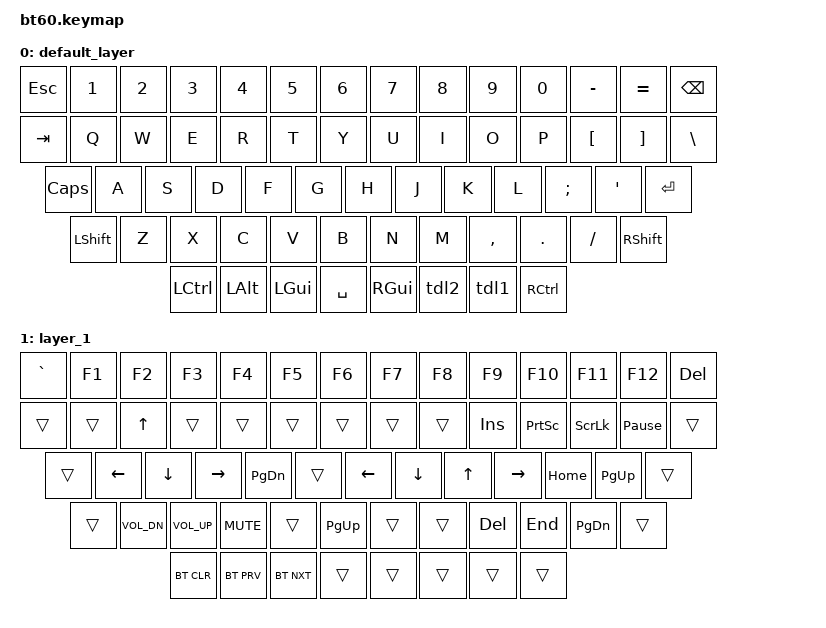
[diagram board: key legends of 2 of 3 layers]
#include <behaviors.dtsi>
#include <dt-bindings/zmk/keys.h>
#include <dt-bindings/zmk/bt.h>
#include <dt-bindings/zmk/rgb.h>
#include <dt-bindings/zmk/backlight.h>

/ {
  // Macros to combine layer tap dance with RGB underglow
  macros {
    m_togl1: macro_rgb_tog_layer_1 {
      compatible = "zmk,behavior-macro";
      #binding-cells = <0>;
      bindings = <&tog 1>,
        <&rgb_ug RGB_TOG>,
        <&rgb_ug RGB_COLOR_HSB(128,100,100)>  // Green
        ;
    };
    m_togl2: macro_rgb_tog_layer_2 {
      compatible = "zmk,behavior-macro";
      #binding-cells = <0>;
      bindings = <&tog 2>,
        <&rgb_ug RGB_TOG>,
        <&rgb_ug RGB_COLOR_HSB(0,100,100)>  // Red
        ;
    };
  };

  behaviors {
    // Tap Dance to change layer, tap once and hold for momentary layer, tap twice to toggle layer
    tdl1: tap_dance_layer_1 {
      compatible = "zmk,behavior-tap-dance";
      #binding-cells = <0>;
      tapping-term-ms = <200>;  // default: 200ms
      bindings = <&mo 1>, <&m_togl1>;
    };
    tdl2: tap_dance_layer_2 {
      compatible = "zmk,behavior-tap-dance";
      #binding-cells = <0>;
      tapping-term-ms = <200>;  // default: 200ms
      bindings = <&mo 2>, <&m_togl2>;
    };
  };


  keymap {
    compatible = "zmk,keymap";

    default_layer {
      // Qwerty
      bindings = <
      // ┏━━━━━━━━━┳━━━━━━━━┳━━━━━━━━┳━━━━━━━━┳━━━━━━━━┳━━━━━━━━┳━━━━━━━━┳━━━━━━━━┳━━━━━━━━┳━━━━━━━━┳━━━━━━━━┳━━━━━━━━━━━┳━━━━━━━━━━━┳━━━━━━━━━━━┓
      // ┃ Esc     ┃ 1      ┃ 2      ┃ 3      ┃ 4      ┃ 5      ┃   6    ┃ 7      ┃ 8      ┃ 9      ┃ 0      ┃ -         ┃ =         ┃ Backspace ┃
           &kp ESC   &kp N1   &kp N2   &kp N3   &kp N4   &kp N5   &kp N6   &kp N7   &kp N8   &kp N9   &kp N0   &kp MINUS   &kp EQUAL   &kp BSPC
      // ┣━━━━━━━━━┻━━━━━━┳━┻━━━━━┳━━┻━━━━┳━━━┻━━━┳━━━━┻━━┳━━━━━┻━┳━━━━━━┻┳━━━━━━━╋━━━━━━━┳┻━━━━━━┳━┻━━━━━┳━━┻━━━━━━━┳━━━┻━━━━━━┳━━━━┻━━━━━━━━━━━┫
      // ┃ Tab            ┃ Q     ┃ W     ┃ E     ┃ R     ┃ T     ┃ Y     ┃ U     ┃ I     ┃ O     ┃ P     ┃ [        ┃ ]        ┃ \              ┃
           &kp TAB          &kp Q   &kp W   &kp E   &kp R   &kp T   &kp Y   &kp U   &kp I   &kp O   &kp P   &kp LBKT   &kp RBKT   &kp BSLH
      // ┣━━━━━━━━━━━━━━━━┻┳━━━━━━┻┳━━━━━━┻┳━━━━━━┻┳━━━━━━┻┳━━━━━━┻┳━━━━━━┻┳━━━━━━┻┳━━━━━━┻┳━━━━━━┻┳━━━━━━┻━━━┳━━━━━━┻━━┳━━━━━━━┻━━━━━━━━━━━━━━━━┫
      // ┃ Caps            ┃ A     ┃ S     ┃ D     ┃ F     ┃ G     ┃ H     ┃ J     ┃ K     ┃ L     ┃ ;        ┃ '       ┃ Enter                  ┃
           &kp CAPS          &kp A   &kp S   &kp D   &kp F   &kp G   &kp H   &kp J   &kp K   &kp L   &kp SEMI   &kp SQT   &kp RET
      // ┣━━━━━━━━━━━━━━━━━┻━┳━━━━━┻━┳━━━━━┻━┳━━━━━┻━┳━━━━━┻━┳━━━━━┻━┳━━━━━┻━┳━━━━━┻━┳━━━━━┻━━━━━┳━┻━━━━━━━┳━━┻━━━━━━━┳━┻━━━━━━━━━━━━━━━━━━━━━━━━┫
      // ┃ Shift             ┃ Z     ┃ X     ┃ C     ┃ V     ┃ B     ┃ N     ┃ M     ┃ ,         ┃ .       ┃ /        ┃ Shift                    ┃
           &kp LSHFT           &kp Z   &kp X   &kp C   &kp V   &kp B   &kp N   &kp M   &kp COMMA   &kp DOT   &kp FSLH   &kp RSHFT
      // ┣━━━━━━━━━━━┳━━━━━━━┻━━┳━━━━┻━━━━━┳━┻━━━━━━━┻━━━━━━━┻━━━━━━━┻━━━━━━━┻━━━━━━━┻━━━━━━━━━━━┻━━━━━━┳━━┻━━━━━━━┳━━━━━━━━┳━━━━━━━━┳━━━━━━━━━━━┫
      // ┃ Ctrl      ┃ Option   ┃ Command  ┃ Space                                                      ┃ Command  ┃ TogL2  ┃ TogL1  ┃ Ctrl      ┃
           &kp LCTRL   &kp LALT   &kp LGUI   &kp SPACE                                                    &kp RGUI   &tdl2    &tdl1    &kp RCTRL
      // ┗━━━━━━━━━━━┻━━━━━━━━━━┻━━━━━━━━━━┻━━━━━━━━━━━━━━━━━━━━━━━━━━━━━━━━━━━━━━━━━━━━━━━━━━━━━━━━━━━━┻━━━━━━━━━━┻━━━━━━━━┻━━━━━━━━┻━━━━━━━━━━━┛
      >;
      sensor-bindings = <&inc_dec_kp C_VOL_UP C_VOL_DN>;
    };
    layer_1 {
      // Function, Arrow, Volume, Bluetooth, Navigation and Vim Keys
      bindings = <
      // ┏━━━━━━━━━━━┳━━━━━━┳━━━━━━━━┳━━━━━━━━┳━━━━━━━━┳━━━━━━━━┳━━━━━━━━┳━━━━━━━━┳━━━━━━━━┳━━━━━━━━┳━━━━━━━━━┳━━━━━━━━━┳━━━━━━━━━┳━━━━━━━━━━━━━━┓
      // ┃ `         ┃ F1   ┃ F2     ┃ F3     ┃ F4     ┃ F5     ┃ F6     ┃ F7     ┃ F8     ┃ F9     ┃ F10     ┃ F11     ┃ F12     ┃ Del          ┃
           &kp GRAVE   &kp F1 &kp F2   &kp F3   &kp F4   &kp F5   &kp F6   &kp F7   &kp F8   &kp F9   &kp F10   &kp F11   &kp F12   &kp DEL
      // ┣━━━━━━━━━━━┻━━━━━━┻━┳━━━━━━┻━┳━━━━━━━━━━━━━━━┻━━━━━━━━┻━━━━━━━━┻━━━━━━━┳┻━━━━━━━━╋━━━━━━━━┻━━┳━━━━━━┻━━━┳━━━━━┻━━━━━━━━━┻━┳━━━━━━━━━━━━┫
      // ┃                    ┃ W ↑    ┃                                         ┃ Ins     ┃ PScrn     ┃ ScrLk    ┃ Pause           ┃            ┃
           &trans      &trans   &kp UP  &trans &trans &trans &trans &trans &trans  &kp INS   &kp PSCRN   &kp SLCK   &kp PAUSE_BREAK  &trans
      // ┣━━━━━━━━━━━━━┳━━━━━━┻━┳━━━━━━┻━┳━━━━━━━━━┳━━━━━━━━━┳━━━━━━┳━━━━━━━━┳━━━┻━━━━┳━━━━┻━┳━━━━━━━━━╋━━━━━━━━┳━┻━━━━━━━┳━━━━━━━━━┻━━━━━━━━━━━━┫
      // ┃             ┃ A ←    ┃ S ↓    ┃ D  →    ┃ F- PgDn ┃      ┃ H ←    ┃ J ↓    ┃ K ↑  ┃ L →     ┃ Home   ┃ PgUp    ┃                      ┃
           &trans       &kp LEFT &kp DOWN &kp RIGHT &kp PG_DN &trans &kp LEFT &kp DOWN &kp UP &kp RIGHT &kp HOME &kp PG_UP  &trans
      // ┣━━━━━━━━━━━━━┻━━━━━┳━━┻━━━━━━━━┻┳━━━━━━━━┻━━━┳━━━━━┻━━━━┳━┻━━━━┳━━━┻━━━━━┳━━┻━━━┳━━┻━━━┳━━━━━┻━┳━━━━━━┻┳━━━━━━━━┻┳━━━━━━━━━━━━━━━━━━━━━┫
      // ┃                   ┃ Z- ♫↓      ┃ X- ♫↑      ┃ C- ♫∅    ┃      ┃ B- PgUp ┃      ┃      ┃ Del   ┃ End   ┃ PgDn    ┃                     ┃
           &trans             &kp C_VOL_DN &kp C_VOL_UP &kp C_MUTE &trans &kp PG_UP &trans &trans &kp DEL &kp END &kp PG_DN  &trans
      // ┣━━━━━━━━━━━┳━━━━━━━┻━━┳━━━━━━━━━┻┳━━━━━━━━━━━┻━━━━━━━━━━┻━━━━━━┻━━━━━━━━━┻━━━━━━┻━━━━━━┻━━━━━━┳┻━━━━━━━┻┳━━━━━━━━╋━━━━━━━━┳━━━━━━━━━━━━┫
      // ┃ BtClr     ┃ BtPrev   ┃ BtNext   ┃                                                            ┃         ┃        ┃        ┃            ┃
           &bt BT_CLR &bt BT_PRV &bt BT_NXT  &trans                                                       &trans    &trans   &trans   &trans
      // ┗━━━━━━━━━━━┻━━━━━━━━━━┻━━━━━━━━━━┻━━━━━━━━━━━━━━━━━━━━━━━━━━━━━━━━━━━━━━━━━━━━━━━━━━━━━━━━━━━━┻━━━━━━━━━┻━━━━━━━━┻━━━━━━━━┻━━━━━━━━━━━━┛
      >;
      sensor-bindings = <&inc_dec_kp C_VOL_UP C_VOL_DN>;
    };
    layer_2 {
      // Keyboard Controls and Vim Keys
      bindings = <
      // ┏━━━━━━┳━━━━━━━━━━━┳━━━━━━━━━━┳━━━━━━━━━━━━━━━┳━━━━━━━━━━┳━━━━━━━━━━┳━━━━━━━━━━┳━━━━━━━━━━┳━━━━━━━━━━┳━━━━━━━━━━┳━━━━━━━━━━━━━━━━━━━━━━━━━━━┓
      // ┃      ┃ 1- Boot.  ┃ 2- Reset ┃ 3- RgbTog     ┃ 4- BlTog ┃ 5- BlInc ┃ 6- BlDec ┃ 7- BtClr ┃ 8- BtPrev┃ 9- BtNxt ┃                           ┃
          &trans &bootloader &sys_reset &rgb_ug RGB_TOG &bl BL_TOG &bl BL_INC &bl BL_DEC &bt BT_CLR &bt BT_PRV &bt BT_NXT &trans &trans &trans &trans
      // ┣━━━━━━┻━━━━━━━━━━━┻━━━━━━━━━━┻━━━━━━━━━━━━━━━┻━━━━━━━━━━┻━━━━━━━━━━┻━━━━━━━━━━┻━━━━━━━━━━┻━━━━━━━━━━┻━━━━━━━━━━┻━━━━━━━━━┻━━━━━━━━━┻━━━━━━━┫
      // ┃                                                                                                                                           ┃
          &trans &trans &trans &trans &trans &trans &trans &trans &trans &trans &trans &trans &trans &trans
      // ┣━━━━━━━━━━━━━┳━━━━━━━━━━━━━━━━━━━━━━━━━━━━━━━┳━━━━━━━━━━━┳━━━━━━┳━━━━━━━━━━┳━━━━━━━━━━┳━━━━━━━━┳━━━━━━━━━━━┳━━━━━━━━━━━━━━━━━━━━━━━━━━━━━━━┫
      // ┃             ┃                               ┃ F- PgDn   ┃      ┃ H ←      ┃ J ↓      ┃ K ↑    ┃ L →       ┃                               ┃
           &trans       &trans &trans &trans             &kp PG_DN  &trans  &kp LEFT   &kp DOWN   &kp UP   &kp RIGHT   &trans &trans &trans &trans
      // ┣━━━━━━━━━━━━━┻━━━━━┳━━━━━━━━━━━━━━━━━━━━━━━━━┻━━━━━━━━━━━┻━━━━┳━┻━━━━━━━━━━╋━━━━━━━━━━┻━━━━━━━━┻━━━━━━━━━━━┻━━━━━━━━━━━━━━━━━━━━━━━━━━━━━━━┫
      // ┃                   ┃                                          ┃ B- PgUp    ┃                                                               ┃
           &trans              &trans &trans &trans &trans                &kp PG_UP    &trans &trans &trans &trans &trans &trans
      // ┣━━━━━━━━━━━┳━━━━━━━┻━━┳━━━━━━━━━━┳━━━━━━━━━━━━━━━━━━━━━━━━━━━━┻━━━━━━━━━━━━┻━━━━━━━━━━━━━━━━━━━━━━━━━━━━━━━━━━━━━━━━━━━━━━━━━━━━━━━━━━━━━━━┫
      // ┃ Ctrl      ┃ Option   ┃ Command  ┃                                                                                                         ┃
           &kp LCTRL   &kp LALT   &kp LGUI   &trans                                                           &trans    &trans   &trans   &trans
      // ┗━━━━━━━━━━━┻━━━━━━━━━━┻━━━━━━━━━━┻━━━━━━━━━━━━━━━━━━━━━━━━━━━━━━━━━━━━━━━━━━━━━━━━━━━━━━━━━━━━━━━━━━━━━━━━━━━━━━━━━━━━━━━━━━━━━━━━━━━━━━━━━┛
      >;
      sensor-bindings = <&inc_dec_kp C_VOL_UP C_VOL_DN>;
    };
  };
};
